AUTOSAR XML (schema 4-3-0)
standard types defined: uint16, uint32, uint8, uint16_DataConstr, uint32_DataConstr, uint8_DataConstr, sint16
package /ComponentTypes/HkmcRadarAdapSWC
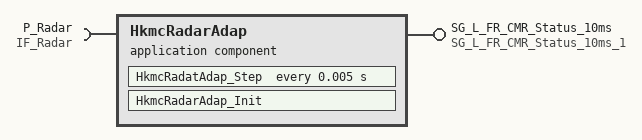
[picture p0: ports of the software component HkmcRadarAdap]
  application sw component type HkmcRadarAdap
    provide port SG_L_FR_CMR_Status_10ms: nonqueued-sender-com-spec{data-element=SG_L_FR_CMR_Status_10ms, init-value=fields=[CLU_OdoVal:0, L_ENG_EngSta:0, L_ENG_IgnOnSta:0, L_FR_CMR_Status_AlvCnt1Val:0, L_FR_CMR_Status_Crc1Val:65535, L_FR_CMR_Status_EstVehDirection:0, L_FR_CMR_Status_EstVehSpdFailure:0, L_FR_CMR_Status_EstVehSpdVal:0, L_FR_CMR_Status_LatAccelVal:32768, L_FR_CMR_Status_LongAccelVal:32768, L_FR_CMR_Status_SAS_AnglVal:0, L_FR_CMR_Status_YawRtCompensated:32768, L_HCU_HevRdySta:0, L_VCU_EVRdySta:0]}, provided-interface=SG_L_FR_CMR_Status_10ms_1
    require port P_Radar: nonqueued-receiver-com-spec{data-element=DE_HkmcRadarAdapInput, filter=data-filter-type=ALWAYS, init-value=constant-reference=CS_RadarAdap_Radar}, required-interface=IF_Radar
    behavior HkmcRadarAdap_InternalBehavior
      init event HkmcRadarAdap_InitEvent: start-on-event=HkmcRadarAdap_Init
      timing event HkmcRadatAdap_Step_TE: start-on-event=HkmcRadatAdap_Step, period=0.005
      runnable HkmcRadarAdap_Init
        data-receive-point-by-arguments:
          access REC_P_Radar_DE_HkmcRadarAdapInput: accessed-variable=P_Radar.DE_HkmcRadarAdapInput
        data-send-points:
          access SEND_SG_L_FR_CMR_Status_10ms_SG_L_FR_CMR_Status_10ms: accessed-variable=SG_L_FR_CMR_Status_10ms.SG_L_FR_CMR_Status_10ms
      runnable HkmcRadatAdap_Step
        data-receive-point-by-arguments:
          access REC_P_Radar_DE_HkmcRadarAdapInput: accessed-variable=P_Radar.DE_HkmcRadarAdapInput
        data-send-points:
          access SEND_SG_L_FR_CMR_Status_10ms_SG_L_FR_CMR_Status_10ms: accessed-variable=SG_L_FR_CMR_Status_10ms.SG_L_FR_CMR_Status_10ms
  swc implementation HkmcRadarAdap_Implementation: behavior=HkmcRadarAdap_InternalBehavior
    code-descriptors:
      code Default: artifact-descriptors=autosar-engineering-object={short-label=Default, category=SWSRC}
package /ComponentTypes/HkmcRadarAdapSWC/Constants
  constant specification CS_RadarAdap_Radar: value-spec=fields=[SAS_AnglVal:0, ESC_YawRtVal:0, ESC_LatAccelVal:0, ESC_LongAccelVal:0, longitudinalSpeed:0, longitudinalSpeedQual:0, WHL_DirFLVal:0, WHL_DirFRVal:0, WHL_DirRLVal:0, WHL_DirRRVal:0, ENG_EngSta:0, HCU_HevRdySta:0, VCU_EVRdySta:0, ENG_IgnOnSta:0, CLU_OdoVal:0]
package /ComponentTypes/HkmcRadarAdapSWC/DataTypes
  impl type Radar_T: category=STRUCTURE, sw-calibration-access=READ-ONLY, type-emitter=RTE
    15 x element, all with category=TYPE_REFERENCE:
      SAS_AnglVal: implementation-data-type=uint8
      ESC_YawRtVal: implementation-data-type=uint8
      ESC_LatAccelVal: implementation-data-type=uint8
      ESC_LongAccelVal: implementation-data-type=uint16
      longitudinalSpeed: implementation-data-type=uint8
      longitudinalSpeedQual: implementation-data-type=uint8
      WHL_DirFLVal: implementation-data-type=uint8
      WHL_DirFRVal: implementation-data-type=uint8
      WHL_DirRLVal: implementation-data-type=uint8
      WHL_DirRRVal: implementation-data-type=uint8
      ENG_EngSta: implementation-data-type=uint8
      HCU_HevRdySta: implementation-data-type=uint8
      VCU_EVRdySta: implementation-data-type=uint8
      ENG_IgnOnSta: implementation-data-type=uint8
      CLU_OdoVal: implementation-data-type=uint32
package /ComponentTypes/HkmcRadarAdapSWC/PortInterfaces
  sender receiver interface IF_Radar: invalidation-policy{data-element=DE_HkmcRadarAdapInput, handle-invalid=DONT-INVALIDATE}
    data DE_HkmcRadarAdapInput: type=Radar_T
package /DataTypes
  15 x impl type:
    CLU_OdoVal: category=VALUE, base-type=DataType/uint32, range raw 0..16777215
    L_ENG_EngSta: category=VALUE, base-type=DataType/uint8, compu {0=Cx0_Engine_Stop_ (Engine Stop), 1=Cx1_Cranking_, 2=Cx2_Stalled_, 3=Cx3_Running_, 4=Cx4_Reserved_, 5=Cx5_Reserved_, 6=Cx6_Reserved_, 7=Cx7_Fault}
    L_ENG_IgnOnSta: category=VALUE, base-type=DataType/uint8, compu {0=Cx0_KEY_OFF_control_unit_in_self_holding_phase_ (KEY OFF, control unit in self-holding phase), 1=Cx1_KEY_ON_ (KEY ON), 2=Cx2_Not_used_ (Not used), 3=Cx3_Error_indicator (Error indicator)}
    L_FR_CMR_Status_AlvCnt1Val: category=VALUE, base-type=DataType/uint8
    L_FR_CMR_Status_Crc1Val: category=VALUE, base-type=DataType/uint16
    L_FR_CMR_Status_EstVehDirection: category=VALUE, base-type=DataType/uint8, compu {0=Cx0_Unknown_Wheel_moving_stop_state_ (Unknown (Wheel moving stop state)), 1=Cx1_Forward_direction_ (Forward direction), 2=Cx2_Backward_direction_ (Backward direction), 3=Cx3_Error_identifier_ (Error identifier), 4=Cx4_Not_applied_wheel_sensor_for_direction (Not applied wheel sensor for direction)}
    L_FR_CMR_Status_EstVehSpdFailure: category=VALUE, base-type=DataType/uint8, compu {0=Cx0_Normal_, 1=Cx1_Failure_, 2=Cx2_Reserved_, 3=Cx3_Reserved_, 4=Cx4_Reserved_, 5=Cx5_Reserved_, 6=Cx6_Reserved_, 7=Cx7_Reserved}
    L_FR_CMR_Status_EstVehSpdVal: category=VALUE, base-type=DataType/uint16
    L_FR_CMR_Status_LatAccelVal: category=VALUE, base-type=DataType/uint16
    L_FR_CMR_Status_LongAccelVal: category=VALUE, base-type=DataType/uint16
    L_FR_CMR_Status_SAS_AnglVal: category=VALUE, base-type=sint16
    L_FR_CMR_Status_YawRtCompensated: category=VALUE, base-type=DataType/uint16
    L_HCU_HevRdySta: category=VALUE, base-type=DataType/uint8, compu {0=Cx0_HEV_not_ready_ (HEV not ready), 1=Cx1_HEV_Drivable_ (HEV Drivable), 2=Cx2_Not_used_ (Not used), 3=Cx3_Error_Indicator (Error Indicator)}
    L_VCU_EVRdySta: category=VALUE, base-type=DataType/uint8, compu {0=Cx0_None_, 1=Cx1_EV_Drivable_ (EV Drivable), 2=Cx2_Not_used_ (Not used), 3=Cx3_Error_Indicator (Error Indicator)}
    SG_L_FR_CMR_Status_10ms: category=STRUCTURE
      14 x element, all with category=TYPE_REFERENCE:
        CLU_OdoVal: range raw 0..16777215, implementation-data-type=CLU_OdoVal
        L_ENG_EngSta: range raw 0..7, implementation-data-type=L_ENG_EngSta
        L_ENG_IgnOnSta: range raw 0..3, implementation-data-type=L_ENG_IgnOnSta
        L_FR_CMR_Status_AlvCnt1Val: range raw 0..255, implementation-data-type=L_FR_CMR_Status_AlvCnt1Val
        L_FR_CMR_Status_Crc1Val: range raw 0..65535, implementation-data-type=L_FR_CMR_Status_Crc1Val
        L_FR_CMR_Status_EstVehDirection: range raw 0..7, implementation-data-type=L_FR_CMR_Status_EstVehDirection
        L_FR_CMR_Status_EstVehSpdFailure: range raw 0..7, implementation-data-type=L_FR_CMR_Status_EstVehSpdFailure
        L_FR_CMR_Status_EstVehSpdVal: implementation-data-type=L_FR_CMR_Status_EstVehSpdVal
        L_FR_CMR_Status_LatAccelVal: implementation-data-type=L_FR_CMR_Status_LatAccelVal
        L_FR_CMR_Status_LongAccelVal: implementation-data-type=L_FR_CMR_Status_LongAccelVal
        L_FR_CMR_Status_SAS_AnglVal: implementation-data-type=L_FR_CMR_Status_SAS_AnglVal
        L_FR_CMR_Status_YawRtCompensated: implementation-data-type=L_FR_CMR_Status_YawRtCompensated
        L_HCU_HevRdySta: range raw 0..3, implementation-data-type=L_HCU_HevRdySta
        L_VCU_EVRdySta: range raw 0..3, implementation-data-type=L_VCU_EVRdySta
package /PortInterfaces
  sender receiver interface SG_L_FR_CMR_Status_10ms_1: invalidation-policy{data-element=SG_L_FR_CMR_Status_10ms, handle-invalid=DONT-INVALIDATE}
    data SG_L_FR_CMR_Status_10ms: type=SG_L_FR_CMR_Status_10ms
